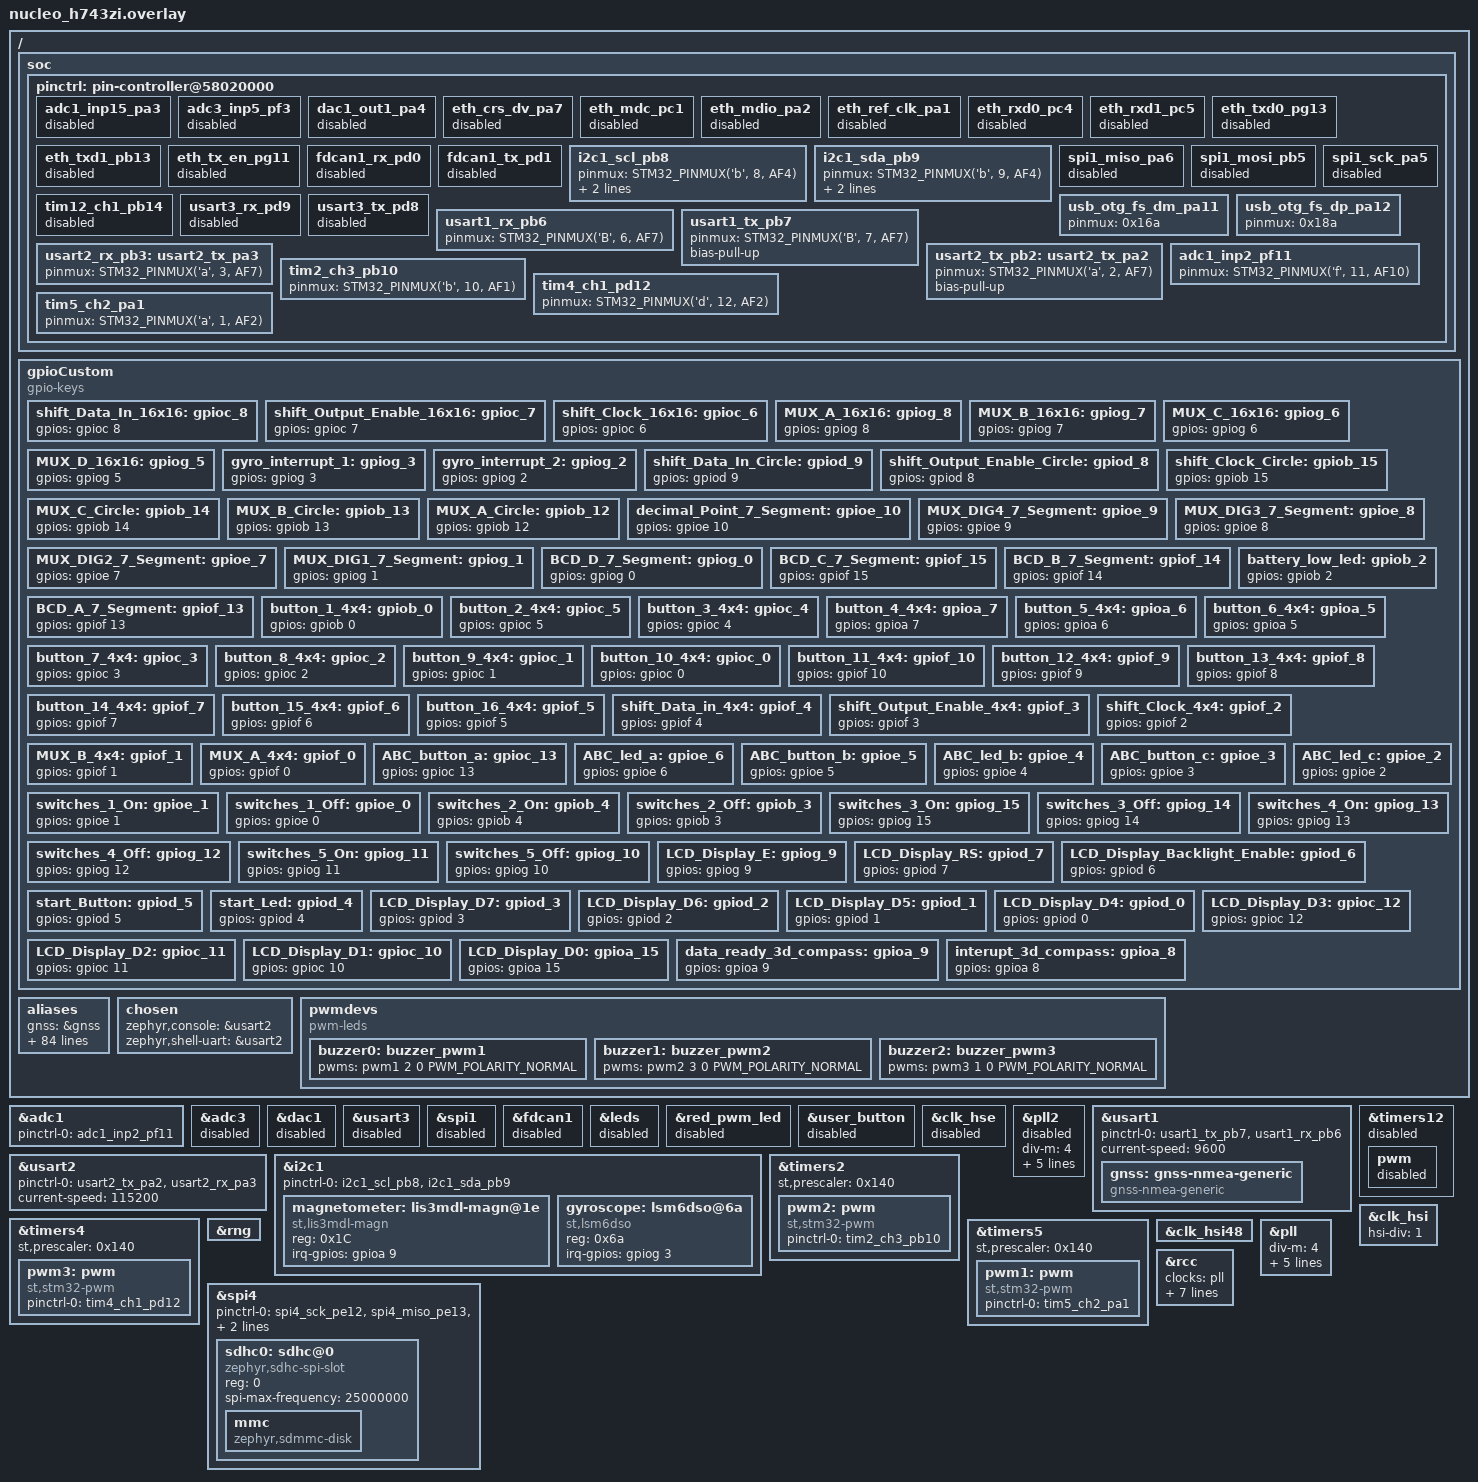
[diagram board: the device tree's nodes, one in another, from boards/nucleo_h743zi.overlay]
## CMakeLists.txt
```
# SPDX-License-Identifier: Apache-2.0

cmake_minimum_required(VERSION 3.20.0)
find_package(Zephyr REQUIRED HINTS $ENV{ZEPHYR_BASE})
project(startweek)

# Gather source files using wildcards for src directory
file(GLOB SRC_HARDWARE_SOURCES 			"../hardware/src/*.c")
file(GLOB SRC_HARDWARECONTROL_SOURCES 	"../hardwareControl/src/*.c")
file(GLOB SRC_MAIN_SOURCES 				"src/*.c")
file(GLOB SRC_STATES_SOURCES 			"../states/src/*.c")
file(GLOB SRC_STATEMACHINE 				"../main/src/statemachine.c")
file(GLOB SRC_THREADS 					"../main/src/threads.c")
file(GLOB SRC_HELPFUNC 					"../main/src/helperFunctions.c")

# Add your source files
target_sources(app PRIVATE 
    ${SRC_HARDWARE_SOURCES}
	${SRC_HARDWARECONTROL_SOURCES}
	${SRC_MAIN_SOURCES}
	${SRC_STATES_SOURCES}
	${SRC_STATEMACHINE}
	${SRC_THREADS}
	${SRC_HELPFUNC}
)

# Add include directories
target_include_directories(app PRIVATE
	${CMAKE_CURRENT_SOURCE_DIR}/../hardware/inc
	${CMAKE_CURRENT_SOURCE_DIR}/../hardwareControl/inc
	${CMAKE_CURRENT_SOURCE_DIR}/../main/inc
	${CMAKE_CURRENT_SOURCE_DIR}/../states/inc
	${CMAKE_CURRENT_SOURCE_DIR}/inc
)

set_property(TARGET app PROPERTY COMPILE_WARNING_AS_ERROR OFF)
```

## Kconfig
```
mainmenu "Startweek options"

menu ":D"

config TEST_RNG_INPUT
    bool "Use RNG input instead of human input"
    default y

config TEST_ACCELEROMETER
    bool "Test the accelerometer"
    default n

config TEST_BUTTONMATRIX
    bool "Test the buttonmatrix"
    default n

config TEST_CIRCLE_MATRIX
    bool "Test the circle matrix"
    default n

config TEST_GENERIC_GPIO
    bool "Test the generic GPIO"
    default n

config TEST_HELPER_FUNCTIONS
    bool "Test helper functions"
    default n

config TEST_INTEGRATION
    bool "Test integration"
    default n

config TEST_LCD
    bool "Test the LCD"
    default n

config TEST_LED_MATRIX
    bool "Test the LED matrix"
    default n

config TEST_SEVEN_SEGMENT
    bool "Test the seven-segment display"
    default n

config TEST_MINIGAME_FUNCTIONS
    bool "Test minigame functions"
    default n

endmenu

source "Kconfig.zephyr"
```

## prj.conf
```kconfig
CONFIG_COMPILER_WARNINGS_AS_ERRORS=y

CONFIG_TEST_RNG_INPUT=y
CONFIG_TEST_ACCELEROMETER=y
CONFIG_TEST_BUTTONMATRIX=y
CONFIG_TEST_CIRCLE_MATRIX=y
CONFIG_TEST_GENERIC_GPIO=y
CONFIG_TEST_HELPER_FUNCTIONS=y
CONFIG_TEST_INTEGRATION=n
CONFIG_TEST_LCD=y
CONFIG_TEST_LED_MATRIX=y
CONFIG_TEST_SEVEN_SEGMENT=y
CONFIG_TEST_MINIGAME_FUNCTIONS=y
```

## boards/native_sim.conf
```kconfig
CONFIG_LV_Z_MEM_POOL_SIZE=163840
CONFIG_LV_Z_SHELL=y
CONFIG_MAIN_STACK_SIZE=16384

CONFIG_GPIO=y
CONFIG_INPUT=y
CONFIG_LOG=y
CONFIG_SHELL=y

CONFIG_DISPLAY=y
CONFIG_EMUL=y
CONFIG_GPIO_EMUL=y
CONFIG_GPIO_EMUL_SDL=y
CONFIG_EMUL_LOG_LEVEL_DBG=y

# LVGL config
CONFIG_LVGL=y
CONFIG_LV_MEM_CUSTOM=y
CONFIG_LV_USE_LOG=y
CONFIG_LV_USE_LABEL=y
CONFIG_LV_USE_BTN=y
CONFIG_LV_USE_ARC=y
CONFIG_LV_USE_IMG=y

CONFIG_ENTROPY_GENERATOR=y

CONFIG_ZTEST=y
```

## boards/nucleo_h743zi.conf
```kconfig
CONFIG_GPIO=y
CONFIG_DEBUG_OPTIMIZATIONS=y
CONFIG_SIZE_OPTIMIZATIONS=n
CONFIG_SPEED_OPTIMIZATIONS=n
CONFIG_ENTROPY_GENERATOR=y

CONFIG_STDOUT_CONSOLE=y
CONFIG_CBPRINTF_FP_SUPPORT=y

CONFIG_I2C=y
CONFIG_SENSOR=y
CONFIG_LSM6DSO_TRIGGER_NONE=y
CONFIG_LIS3MDL_ODR="155"

CONFIG_LSM6DSO=y
CONFIG_LSM6DSO_TRIGGER_NONE=y
CONFIG_PWM=y

#CONFIG_GNSS=y
#CONFIG_GNSS_SATELLITES=y

#CONFIG_UART_INTERRUPT_DRIVEN=y
#CONFIG_MODEM_MODULES=y

#CONFIG_GNSS_SATELLITES=y
CONFIG_STM32_VREF=n
CONFIG_STM32_VBAT=n
CONFIG_STM32_TEMP=n

CONFIG_DISK_ACCESS=y
CONFIG_FILE_SYSTEM=y
#CONFIG_FILE_SYSTEM_SHELL=y
CONFIG_FAT_FILESYSTEM_ELM=y
CONFIG_MAIN_STACK_SIZE=2024
CONFIG_HEAP_MEM_POOL_SIZE=8192
CONFIG_ZTEST=y
```

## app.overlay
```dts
/ {
	soc {
		pinctrl: pin-controller@58020000 {
			//disable pins
			adc1_inp15_pa3: adc1_inp15_pa3 {
				status = "disabled";
			};
			adc3_inp5_pf3: adc3_inp5_pf3 {
				status = "disabled";
			};
			dac1_out1_pa4: dac1_out1_pa4 {
				status = "disabled";
			};
			eth_crs_dv_pa7: eth_crs_dv_pa7 {
				status = "disabled";
			};
			eth_mdc_pc1: eth_mdc_pc1 {
				status = "disabled";
			};
			eth_mdio_pa2: eth_mdio_pa2 {
				status = "disabled";
			};
			eth_ref_clk_pa1: eth_ref_clk_pa1 {
				status = "disabled";
			};
			eth_rxd0_pc4: eth_rxd0_pc4 {
				status = "disabled";
			};
			eth_rxd1_pc5: eth_rxd1_pc5 {
				status = "disabled";
			};
			eth_txd0_pg13: eth_txd0_pg13 {
				status = "disabled";
			};
			eth_txd1_pb13: eth_txd1_pb13 {
				status = "disabled";
			};
			eth_tx_en_pg11: eth_tx_en_pg11 {
				status = "disabled";
			};
			fdcan1_rx_pd0: fdcan1_rx_pd0 {
				status = "disabled";
			};
			fdcan1_tx_pd1: fdcan1_tx_pd1 {
				status = "disabled";
			};
			i2c1_scl_pb8: i2c1_scl_pb8 {
				status = "disabled";
			};
			i2c1_sda_pb9: i2c1_sda_pb9 {
				status = "disabled";
			};
			spi1_miso_pa6: spi1_miso_pa6 {
				status = "disabled";
			};
			spi1_mosi_pb5: spi1_mosi_pb5 {
				status = "disabled";
			};
			spi1_sck_pa5: spi1_sck_pa5 {
				status = "disabled";
			};
			tim12_ch1_pb14: tim12_ch1_pb14 {
				status = "okay";
			};
			usart3_rx_pd9: usart3_rx_pd9 {
				status = "disabled";
			};
			usart3_tx_pd8: usart3_tx_pd8 {
				status = "disabled";
			};

			//enable and configure pins
			usb_otg_fs_dm_pa11: usb_otg_fs_dm_pa11 {
				pinmux = < 0x16a >;
				phandle = < 0x22 >;
				status = "okay";
			};
			usb_otg_fs_dp_pa12: usb_otg_fs_dp_pa12 {
				pinmux = < 0x18a >;
				phandle = < 0x23 >;
				status = "okay";
			};
			usart1_rx_pb6: usart1_rx_pb6 {
				pinmux = <STM32_PINMUX('B', 6, AF7)>;
				status = "okay";
			};
			usart1_tx_pb7: usart1_tx_pb7 {
				pinmux = <STM32_PINMUX('B', 7, AF7)>;
				bias-pull-up;
				status = "okay";
			};
			usart2_rx_pb3: usart2_tx_pa3 {
				pinmux = <STM32_PINMUX('a', 3, AF7)>;
				status = "okay";
			};
			usart2_tx_pb2: usart2_tx_pa2 {
				pinmux = <STM32_PINMUX('a', 2, AF7)>;
				bias-pull-up;
				status = "okay";
			};
			i2c1_scl_pb8: i2c1_scl_pb8 {
				pinmux = < 0x304 >;
				bias-pull-up;
				drive-open-drain;
				status = "okay";
				phandle = < 0xb >;
			};
			i2c1_sda_pb9: i2c1_sda_pb9 {
				pinmux = < 0x324 >;
				bias-pull-up;
				drive-open-drain;
				status = "okay";
				phandle = < 0xc >;
			};
			adc1_inp2_pf11: adc1_inp2_pf11 {
				pinmux = <STM32_PINMUX('f', 11, AF10)>;
				status = "okay";
			};
		};
	};

	gpioCustom {
		compatible = "gpio-keys";

		shift_Data_In_16x16: gpioc_8 {
			gpios = <&gpioc 8 GPIO_ACTIVE_HIGH>;
		};
		shift_Output_Enable_16x16: gpioc_7 {
			gpios = <&gpioc 7 GPIO_ACTIVE_HIGH>;
		};
		shift_Clock_16x16: gpioc_6 {
			gpios = <&gpioc 6 GPIO_ACTIVE_HIGH>;
		};
		MUX_A_16x16: gpiog_8 {
			gpios = <&gpiog 8 GPIO_ACTIVE_HIGH>;
		};
		MUX_B_16x16: gpiog_7 {
			gpios = <&gpiog 7 GPIO_ACTIVE_HIGH>;
		};
		MUX_C_16x16: gpiog_6 {
			gpios = <&gpiog 6 GPIO_ACTIVE_HIGH>;
		};
		MUX_D_16x16: gpiog_5 {
			gpios = <&gpiog 5 GPIO_ACTIVE_HIGH>;
		};
		gyro_interrupt_1: gpiog_3 {
			gpios = <&gpiog 3 GPIO_ACTIVE_HIGH>;
		};
		gyro_interrupt_2: gpiog_2 {
			gpios = <&gpiog 2 GPIO_ACTIVE_HIGH>;
		};
		shift_Data_In_Circle: gpiod_9 {
			gpios = <&gpiod 9 GPIO_ACTIVE_HIGH>;
		};
		shift_Output_Enable_Circle: gpiod_8 {
			gpios = <&gpiod 8 GPIO_ACTIVE_HIGH>;
		};
		shift_Clock_Circle: gpiob_15 {
			gpios = <&gpiob 15 GPIO_ACTIVE_HIGH>;
		};
		MUX_C_Circle: gpiob_14 {
			gpios = <&gpiob 14 GPIO_ACTIVE_HIGH>;
		};
		MUX_B_Circle: gpiob_13 {
			gpios = <&gpiob 13 GPIO_ACTIVE_HIGH>;
		};
		MUX_A_Circle: gpiob_12 {
			gpios = <&gpiob 12 GPIO_ACTIVE_HIGH>;
		};
		buzzer3: gpioe_14 {
			gpios = <&gpioe 14 GPIO_ACTIVE_HIGH>;
		};
		buzzer2: gpioe_13 {
			gpios = <&gpioe 13 GPIO_ACTIVE_HIGH>;
		};
		buzzer1: gpioe_12 {
			gpios = <&gpioe 12 GPIO_ACTIVE_HIGH>;
		};
		decimal_Point_7_Segment: gpioe_10 {
			gpios = <&gpioe 10 GPIO_ACTIVE_HIGH>;
		};
		MUX_DIG4_7_Segment: gpioe_9 {
			gpios = <&gpioe 9 GPIO_ACTIVE_HIGH>;
		};
		MUX_DIG3_7_Segment: gpioe_8 {
			gpios = <&gpioe 8 GPIO_ACTIVE_HIGH>;
		};
		MUX_DIG2_7_Segment: gpioe_7 {
			gpios = <&gpioe 7 GPIO_ACTIVE_HIGH>;
		};
		MUX_DIG1_7_Segment: gpiog_1 {
			gpios = <&gpiog 1 GPIO_ACTIVE_HIGH>;
		};
		BCD_D_7_Segment: gpiog_0 {
			gpios = <&gpiog 0 GPIO_ACTIVE_HIGH>;
		};
		BCD_C_7_Segment: gpiof_15 {
			gpios = <&gpiof 15 GPIO_ACTIVE_HIGH>;
		};
		BCD_B_7_Segment: gpiof_14 {
			gpios = <&gpiof 14 GPIO_ACTIVE_HIGH>;
		};
		BCD_A_7_Segment: gpiof_13 {
			gpios = <&gpiof 13 GPIO_ACTIVE_HIGH>;
		};
		battery_low_led: gpiob_2 {
			gpios = <&gpiob 2 GPIO_ACTIVE_HIGH>;
		};
		button_1_4x4: gpiob_0 {
			gpios = <&gpiob 0 GPIO_PULL_UP>;
		};
		button_2_4x4: gpioc_5 {
			gpios = <&gpioc 5 GPIO_PULL_UP>;
		};
		button_3_4x4: gpioc_4 {
			gpios = <&gpioc 4 GPIO_PULL_UP>;
		};
		button_4_4x4: gpioa_7 {
			gpios = <&gpioa 7 GPIO_PULL_UP>;
		};
		button_5_4x4: gpioa_6 {
			gpios = <&gpioa 6 GPIO_PULL_UP>;
		};
		button_6_4x4: gpioa_5 {
			gpios = <&gpioa 5 GPIO_PULL_UP>;
		};
		button_7_4x4: gpioc_3 {
			gpios = <&gpioc 3 GPIO_PULL_UP>;
		};
		button_8_4x4: gpioc_2 {
			gpios = <&gpioc 2 GPIO_PULL_UP>;
		};
		button_9_4x4: gpioc_1 {
			gpios = <&gpioc 1 GPIO_PULL_UP>;
		};
		button_10_4x4: gpioc_0 {
			gpios = <&gpioc 0 GPIO_PULL_UP>;
		};
		button_11_4x4: gpiof_10 {
			gpios = <&gpiof 10 GPIO_PULL_UP>;
		};
		button_12_4x4: gpiof_9 {
			gpios = <&gpiof 9 GPIO_PULL_UP>;
		};
		button_13_4x4: gpiof_8 {
			gpios = <&gpiof 8 GPIO_PULL_UP>;
		};
		button_14_4x4: gpiof_7 {
			gpios = <&gpiof 7 GPIO_PULL_UP>;
		};
		button_15_4x4: gpiof_6 {
			gpios = <&gpiof 6 GPIO_PULL_UP>;
		};
		button_16_4x4: gpiof_5 {
			gpios = <&gpiof 5 GPIO_PULL_UP>;
		};
		shift_Data_in_4x4: gpiof_4 {
			gpios = <&gpiof 4 GPIO_ACTIVE_HIGH>;
		};
		shift_Output_Enable_4x4: gpiof_3 {
			gpios = <&gpiof 3 GPIO_ACTIVE_HIGH>;
		};
		shift_Clock_4x4: gpiof_2 {
			gpios = <&gpiof 2 GPIO_ACTIVE_HIGH>;
		};
		MUX_B_4x4: gpiof_1 {
			gpios = <&gpiof 1 GPIO_ACTIVE_HIGH>;
		};
		MUX_A_4x4: gpiof_0 {
			gpios = <&gpiof 0 GPIO_ACTIVE_HIGH>;
		};
		ABC_button_a: gpioc_13 {
			gpios = <&gpioc 13 GPIO_PULL_UP>;
		};
		ABC_led_a: gpioe_6 {
			gpios = <&gpioe 6 GPIO_ACTIVE_HIGH>;
		};
		ABC_button_b: gpioe_5 {
			gpios = <&gpioe 5 GPIO_PULL_UP>;
		};
		ABC_led_b: gpioe_4 {
			gpios = <&gpioe 4 GPIO_ACTIVE_HIGH>;
		};
		ABC_button_c: gpioe_3 {
			gpios = <&gpioe 3 GPIO_PULL_UP>;
		};
		ABC_led_c: gpioe_2 {
			gpios = <&gpioe 2 GPIO_ACTIVE_HIGH>;
		};
		switches_1_On: gpioe_1 {
			gpios = <&gpioe 1 GPIO_PULL_UP>;
		};
		switches_1_Off: gpioe_0 {
			gpios = <&gpioe 0 GPIO_PULL_UP>;
		};
		switches_2_On: gpiob_4 {
			gpios = <&gpiob 4 GPIO_PULL_UP>;
		};
		switches_2_Off: gpiob_3 {
			gpios = <&gpiob 3 GPIO_PULL_UP>;
		};
		switches_3_On: gpiog_15 {
			gpios = <&gpiog 15 GPIO_PULL_UP>;
		};
		switches_3_Off: gpiog_14 {
			gpios = <&gpiog 14 GPIO_PULL_UP>;
		};
		switches_4_On: gpiog_13 {
			gpios = <&gpiog 13 GPIO_PULL_UP>;
		};
		switches_4_Off: gpiog_12 {
			gpios = <&gpiog 12 GPIO_PULL_UP>;
		};
		switches_5_On: gpiog_11 {
			gpios = <&gpiog 11 GPIO_PULL_UP>;
		};
		switches_5_Off: gpiog_10 {
			gpios = <&gpiog 10 GPIO_PULL_UP>;
		};
		LCD_Display_E: gpiog_9 {
			gpios = <&gpiog 9 GPIO_ACTIVE_HIGH>;
		};
		LCD_Display_RS: gpiod_7 {
			gpios = <&gpiod 7 GPIO_ACTIVE_HIGH>;
		};
		LCD_Display_Backlight_Enable: gpiod_6 {
			gpios = <&gpiod 6 GPIO_ACTIVE_HIGH>;
		};
		start_Button: gpiod_5 {
			gpios = <&gpiod 5 GPIO_PULL_UP>;
		};
		start_Led: gpiod_4 {
			gpios = <&gpiod 4 GPIO_ACTIVE_HIGH>;
		};
		LCD_Display_D7: gpiod_3 {
			gpios = <&gpiod 3 GPIO_ACTIVE_HIGH>;
		};
		LCD_Display_D6: gpiod_2 {
			gpios = <&gpiod 2 GPIO_ACTIVE_HIGH>;
		};
		LCD_Display_D5: gpiod_1 {
			gpios = <&gpiod 1 GPIO_ACTIVE_HIGH>;
		};
		LCD_Display_D4: gpiod_0 {
			gpios = <&gpiod 0 GPIO_ACTIVE_HIGH>;
		};
		LCD_Display_D3: gpioc_12 {
			gpios = <&gpioc 12 GPIO_ACTIVE_HIGH>;
		};
		LCD_Display_D2: gpioc_11 {
			gpios = <&gpioc 11 GPIO_ACTIVE_HIGH>;
		};
		LCD_Display_D1: gpioc_10 {
			gpios = <&gpioc 10 GPIO_ACTIVE_HIGH>;
		};
		LCD_Display_D0: gpioa_15 {
			gpios = <&gpioa 15 GPIO_ACTIVE_HIGH>;
		};
		data_ready_3d_compass: gpioa_9 {
			gpios = <&gpioa 9 GPIO_PULL_UP>;
		};
		interupt_3d_compass: gpioa_8 {
			gpios = <&gpioa 8 GPIO_PULL_UP>;
		};

	};

	aliases {
		gnss = &gnss;
		shiftdatain16x16 = &shift_Data_In_16x16;
		shiftenable16x16 = &shift_Output_Enable_16x16;
		shiftclock16x16 = &shift_Clock_16x16;
		muxa16x16 = &MUX_A_16x16;
		muxb16x16 = &MUX_B_16x16;
		muxc16x16 = &MUX_C_16x16;
		muxd16x16 = &MUX_D_16x16;
		gyrointerrupt1 = &gyro_interrupt_1;
		gyrointerrupt2 = &gyro_interrupt_2;
		shiftdataincircle = &shift_Data_In_Circle;
		shiftoutputenablecircle = &shift_Output_Enable_Circle;
		shiftclockcircle = &shift_Clock_Circle;
		muxacircle = &MUX_A_Circle;
		muxbcircle = &MUX_B_Circle;
		muxccircle = &MUX_C_Circle;
		buzzer1 = &buzzer1;
		buzzer2 = &buzzer2;
		buzzer3 = &buzzer3;
		decimalpoint7segment = &decimal_Point_7_Segment;
		muxdig17segment = &MUX_DIG1_7_Segment;
		muxdig27segment = &MUX_DIG2_7_Segment;
		muxdig37segment = &MUX_DIG3_7_Segment;
		muxdig47segment = &MUX_DIG4_7_Segment;
		bcdd7segment = &BCD_D_7_Segment;
		bcdc7segment = &BCD_C_7_Segment;
		bcdb7segment = &BCD_B_7_Segment;
		bcda7segment = &BCD_A_7_Segment;
		batterylowled = &battery_low_led;		
		button14x4 = &button_1_4x4;
		button24x4 = &button_2_4x4;
		button34x4 = &button_3_4x4;
		button44x4 = &button_4_4x4;
		button54x4 = &button_5_4x4;
		button64x4 = &button_6_4x4;
		button74x4 = &button_7_4x4;
		button84x4 = &button_8_4x4;
		button94x4 = &button_9_4x4;
		button104x4 = &button_10_4x4;
		button114x4 = &button_11_4x4;
		button124x4 = &button_12_4x4;
		button134x4 = &button_13_4x4;
		button144x4 = &button_14_4x4;
		button154x4 = &button_15_4x4;
		button164x4 = &button_16_4x4;
		shiftdatain4x4 = &shift_Data_in_4x4;
		shiftoutputenable4x4 = &shift_Output_Enable_4x4;
		shiftclock4x4 = &shift_Clock_4x4;
		muxa4x4 = &MUX_A_4x4;
		muxb4x4 = &MUX_B_4x4;
		abcbuttona = &ABC_button_a;
		abcleda = &ABC_led_a;
		abcbuttonb = &ABC_button_b;
		abcledb = &ABC_led_b;
		abcbuttonc = &ABC_button_c;
		abcledc = &ABC_led_c;
		switches1on = &switches_1_On;
		switches1off = &switches_1_Off;
		switches2on = &switches_2_On;
		switches2off = &switches_2_Off;
		switches3on = &switches_3_On;
		switches3off = &switches_3_Off;
		switches4on = &switches_4_On;
		switches4off = &switches_4_Off;
		switches5on = &switches_5_On;
		switches5off = &switches_5_Off;
		lcddisplaye = &LCD_Display_E;
		lcddisplayrs = &LCD_Display_RS;
		lcddisplaybacklightenable = &LCD_Display_Backlight_Enable;
		startbutton = &start_Button;
		startled = &start_Led;
		lcddisplayd7 = &LCD_Display_D7;
		lcddisplayd6 = &LCD_Display_D6;
		lcddisplayd5 = &LCD_Display_D5;
		lcddisplayd4 = &LCD_Display_D4;
		lcddisplayd3 = &LCD_Display_D3;
		lcddisplayd2 = &LCD_Display_D2;
		lcddisplayd1 = &LCD_Display_D1;
		lcddisplayd0 = &LCD_Display_D0;
		3dcompassdataready = &data_ready_3d_compass;
		3dcompassintterupt = &interupt_3d_compass;
	};

	 chosen {
		zephyr,console = &usart2;
		zephyr,shell-uart = &usart2;
	};
};


//disable unused


&adc1{
		status = "okay";
		pinctrl-0 = < &adc1_inp2_pf11 >;
};

&adc3{
		status = "disabled";
};

&dac1{
		status = "disabled";
};

&usart3 {
		status = "disabled";
};

&spi1 {
		status = "disabled";
};

&fdcan1{
		status = "disabled";
};



&leds{
		status = "disabled";
};

&red_pwm_led {
		status = "disabled";
};

&user_button {
		status = "disabled";
};

&clk_hse {
		status = "disabled";
};

//enable used

&usart1 {
		pinctrl-0 = < &usart1_tx_pb7 &usart1_rx_pb6 >;
		pinctrl-names = "default";
        current-speed = <9600>;
        status = "okay";
        gnss: gnss-nmea-generic {
                compatible = "gnss-nmea-generic";
        };
};

&usart2 {
		pinctrl-0 = < &usart2_tx_pa2 &usart2_rx_pa3 >;
		pinctrl-names = "default";
        current-speed = <115200>;
        status = "okay";
};


&i2c1{
		status = "okay";
		pinctrl-0 = < &i2c1_scl_pb8 &i2c1_sda_pb9 >;
		gyro: lis3mdl-magn@1e {
			compatible = "st,lis3mdl-magn";
			reg = <0x1E>;
			irq-gpios = <&gpiob 8 GPIO_ACTIVE_HIGH>;
		};
};

&clk_hsi{
	status = "okay";
	hsi-div = <1>;
};

&clk_hsi48{
	status = "okay";
};

&rng{
	status = "okay";
};

&pll {
	div-m = <4>;
	mul-n = <40>;
	div-p = <2>;
	div-q = <3>;
	div-r = <2>;
	clocks = <&clk_hsi>;
	status = "okay";
};

&rcc {
	clocks = <&pll>;
	clock-frequency = <DT_FREQ_M(320)>;
	d1cpre = < 0x1 >;
	hpre = < 0x2 >;
	d1ppre = < 0x2 >;
	d2ppre1 = < 0x2 >;
	d2ppre2 = < 0x2 >;
	d3ppre = < 0x2 >;
};
```

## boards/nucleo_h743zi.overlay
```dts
/ {
	soc {
		pinctrl: pin-controller@58020000 {
			//disable pins
			adc1_inp15_pa3: adc1_inp15_pa3 {
				status = "disabled";
			};
			adc3_inp5_pf3: adc3_inp5_pf3 {
				status = "disabled";
			};
			dac1_out1_pa4: dac1_out1_pa4 {
				status = "disabled";
			};
			eth_crs_dv_pa7: eth_crs_dv_pa7 {
				status = "disabled";
			};
			eth_mdc_pc1: eth_mdc_pc1 {
				status = "disabled";
			};
			eth_mdio_pa2: eth_mdio_pa2 {
				status = "disabled";
			};
			eth_ref_clk_pa1: eth_ref_clk_pa1 {
				status = "disabled";
			};
			eth_rxd0_pc4: eth_rxd0_pc4 {
				status = "disabled";
			};
			eth_rxd1_pc5: eth_rxd1_pc5 {
				status = "disabled";
			};
			eth_txd0_pg13: eth_txd0_pg13 {
				status = "disabled";
			};
			eth_txd1_pb13: eth_txd1_pb13 {
				status = "disabled";
			};
			eth_tx_en_pg11: eth_tx_en_pg11 {
				status = "disabled";
			};
			fdcan1_rx_pd0: fdcan1_rx_pd0 {
				status = "disabled";
			};
			fdcan1_tx_pd1: fdcan1_tx_pd1 {
				status = "disabled";
			};
			i2c1_scl_pb8: i2c1_scl_pb8 {
				status = "okay";
			};
			i2c1_sda_pb9: i2c1_sda_pb9 {
				status = "okay";
			};
			spi1_miso_pa6: spi1_miso_pa6 {
				status = "disabled";
			};
			spi1_mosi_pb5: spi1_mosi_pb5 {
				status = "disabled";
			};
			spi1_sck_pa5: spi1_sck_pa5 {
				status = "disabled";
			};
			tim12_ch1_pb14: tim12_ch1_pb14 {
				status = "disabled";
			};
			usart3_rx_pd9: usart3_rx_pd9 {
				status = "disabled";
			};
			usart3_tx_pd8: usart3_tx_pd8 {
				status = "disabled";
			};

			//enable and configure pins
			usb_otg_fs_dm_pa11: usb_otg_fs_dm_pa11 {
				pinmux = < 0x16a >;
				phandle = < 0x22 >;
				status = "okay";
			};
			usb_otg_fs_dp_pa12: usb_otg_fs_dp_pa12 {
				pinmux = < 0x18a >;
				phandle = < 0x23 >;
				status = "okay";
			};
			usart1_rx_pb6: usart1_rx_pb6 {
				pinmux = <STM32_PINMUX('B', 6, AF7)>;
				status = "okay";
			};
			usart1_tx_pb7: usart1_tx_pb7 {
				pinmux = <STM32_PINMUX('B', 7, AF7)>;
				bias-pull-up;
				status = "okay";
			};
			usart2_rx_pb3: usart2_tx_pa3 {
				pinmux = <STM32_PINMUX('a', 3, AF7)>;
				status = "okay";
			};
			usart2_tx_pb2: usart2_tx_pa2 {
				pinmux = <STM32_PINMUX('a', 2, AF7)>;
				bias-pull-up;
				status = "okay";
			};
			i2c1_scl_pb8: i2c1_scl_pb8 {
				pinmux = <STM32_PINMUX('b', 8, AF4)>;
				bias-pull-up;
				drive-open-drain;
				status = "okay";
				phandle = < 0xb >;
			};
			i2c1_sda_pb9: i2c1_sda_pb9 {
				pinmux = <STM32_PINMUX('b', 9, AF4)>;
				bias-pull-up;
				drive-open-drain;
				status = "okay";
				phandle = < 0xc >;
			};
			adc1_inp2_pf11: adc1_inp2_pf11 {
				pinmux = <STM32_PINMUX('f', 11, AF10)>;
				status = "okay";
			};
			tim2_ch3_pb10: tim2_ch3_pb10{
				pinmux = <STM32_PINMUX('b', 10, AF1)>;
				status = "okay";
			};
			tim4_ch1_pd12: tim4_ch1_pd12{
				pinmux = <STM32_PINMUX('d', 12, AF2)>;
				status = "okay";
			};
			tim5_ch2_pa1: tim5_ch2_pa1{
				pinmux = <STM32_PINMUX('a', 1, AF2)>;
				status = "okay";
			};
		};
	};

	gpioCustom {
		compatible = "gpio-keys";

		shift_Data_In_16x16: gpioc_8 {
			gpios = <&gpioc 8 GPIO_ACTIVE_HIGH>;
		};
		shift_Output_Enable_16x16: gpioc_7 {
			gpios = <&gpioc 7 GPIO_ACTIVE_HIGH>;
		};
		shift_Clock_16x16: gpioc_6 {
			gpios = <&gpioc 6 GPIO_ACTIVE_HIGH>;
		};
		MUX_A_16x16: gpiog_8 {
			gpios = <&gpiog 8 GPIO_ACTIVE_HIGH>;
		};
		MUX_B_16x16: gpiog_7 {
			gpios = <&gpiog 7 GPIO_ACTIVE_HIGH>;
		};
		MUX_C_16x16: gpiog_6 {
			gpios = <&gpiog 6 GPIO_ACTIVE_HIGH>;
		};
		MUX_D_16x16: gpiog_5 {
			gpios = <&gpiog 5 GPIO_ACTIVE_HIGH>;
		};
		gyro_interrupt_1: gpiog_3 {
			gpios = <&gpiog 3 GPIO_ACTIVE_HIGH>;
		};
		gyro_interrupt_2: gpiog_2 {
			gpios = <&gpiog 2 GPIO_ACTIVE_HIGH>;
		};
		shift_Data_In_Circle: gpiod_9 {
			gpios = <&gpiod 9 GPIO_ACTIVE_HIGH>;
		};
		shift_Output_Enable_Circle: gpiod_8 {
			gpios = <&gpiod 8 GPIO_ACTIVE_HIGH>;
		};
		shift_Clock_Circle: gpiob_15 {
			gpios = <&gpiob 15 GPIO_ACTIVE_HIGH>;
		};
		MUX_C_Circle: gpiob_14 {
			gpios = <&gpiob 14 GPIO_ACTIVE_HIGH>;
		};
		MUX_B_Circle: gpiob_13 {
			gpios = <&gpiob 13 GPIO_ACTIVE_HIGH>;
		};
		MUX_A_Circle: gpiob_12 {
			gpios = <&gpiob 12 GPIO_ACTIVE_HIGH>;
		};
		decimal_Point_7_Segment: gpioe_10 {
			gpios = <&gpioe 10 GPIO_ACTIVE_HIGH>;
		};
		MUX_DIG4_7_Segment: gpioe_9 {
			gpios = <&gpioe 9 GPIO_ACTIVE_HIGH>;
		};
		MUX_DIG3_7_Segment: gpioe_8 {
			gpios = <&gpioe 8 GPIO_ACTIVE_HIGH>;
		};
		MUX_DIG2_7_Segment: gpioe_7 {
			gpios = <&gpioe 7 GPIO_ACTIVE_HIGH>;
		};
		MUX_DIG1_7_Segment: gpiog_1 {
			gpios = <&gpiog 1 GPIO_ACTIVE_HIGH>;
		};
		BCD_D_7_Segment: gpiog_0 {
			gpios = <&gpiog 0 GPIO_ACTIVE_HIGH>;
		};
		BCD_C_7_Segment: gpiof_15 {
			gpios = <&gpiof 15 GPIO_ACTIVE_HIGH>;
		};
		BCD_B_7_Segment: gpiof_14 {
			gpios = <&gpiof 14 GPIO_ACTIVE_HIGH>;
		};
		BCD_A_7_Segment: gpiof_13 {
			gpios = <&gpiof 13 GPIO_ACTIVE_HIGH>;
		};
		battery_low_led: gpiob_2 {
			gpios = <&gpiob 2 GPIO_ACTIVE_HIGH>;
		};
		button_1_4x4: gpiob_0 {
			gpios = <&gpiob 0 GPIO_PULL_UP>;
		};
		button_2_4x4: gpioc_5 {
			gpios = <&gpioc 5 GPIO_PULL_UP>;
		};
		button_3_4x4: gpioc_4 {
			gpios = <&gpioc 4 GPIO_PULL_UP>;
		};
		button_4_4x4: gpioa_7 {
			gpios = <&gpioa 7 GPIO_PULL_UP>;
		};
		button_5_4x4: gpioa_6 {
			gpios = <&gpioa 6 GPIO_PULL_UP>;
		};
		button_6_4x4: gpioa_5 {
			gpios = <&gpioa 5 GPIO_PULL_UP>;
		};
		button_7_4x4: gpioc_3 {
			gpios = <&gpioc 3 GPIO_PULL_UP>;
		};
		button_8_4x4: gpioc_2 {
			gpios = <&gpioc 2 GPIO_PULL_UP>;
		};
		button_9_4x4: gpioc_1 {
			gpios = <&gpioc 1 GPIO_PULL_UP>;
		};
		button_10_4x4: gpioc_0 {
			gpios = <&gpioc 0 GPIO_PULL_UP>;
		};
		button_11_4x4: gpiof_10 {
			gpios = <&gpiof 10 GPIO_PULL_UP>;
		};
		button_12_4x4: gpiof_9 {
			gpios = <&gpiof 9 GPIO_PULL_UP>;
		};
		button_13_4x4: gpiof_8 {
			gpios = <&gpiof 8 GPIO_PULL_UP>;
		};
		button_14_4x4: gpiof_7 {
			gpios = <&gpiof 7 GPIO_PULL_UP>;
		};
		button_15_4x4: gpiof_6 {
			gpios = <&gpiof 6 GPIO_PULL_UP>;
		};
		button_16_4x4: gpiof_5 {
			gpios = <&gpiof 5 GPIO_PULL_UP>;
		};
		shift_Data_in_4x4: gpiof_4 {
			gpios = <&gpiof 4 GPIO_ACTIVE_HIGH>;
		};
		shift_Output_Enable_4x4: gpiof_3 {
			gpios = <&gpiof 3 GPIO_ACTIVE_HIGH>;
		};
		shift_Clock_4x4: gpiof_2 {
			gpios = <&gpiof 2 GPIO_ACTIVE_HIGH>;
		};
		MUX_B_4x4: gpiof_1 {
			gpios = <&gpiof 1 GPIO_ACTIVE_HIGH>;
		};
		MUX_A_4x4: gpiof_0 {
			gpios = <&gpiof 0 GPIO_ACTIVE_HIGH>;
		};
		ABC_button_a: gpioc_13 {
			gpios = <&gpioc 13 GPIO_PULL_UP>;
		};
		ABC_led_a: gpioe_6 {
			gpios = <&gpioe 6 GPIO_ACTIVE_HIGH>;
		};
		ABC_button_b: gpioe_5 {
			gpios = <&gpioe 5 GPIO_PULL_UP>;
		};
		ABC_led_b: gpioe_4 {
			gpios = <&gpioe 4 GPIO_ACTIVE_HIGH>;
		};
		ABC_button_c: gpioe_3 {
			gpios = <&gpioe 3 GPIO_PULL_UP>;
		};
		ABC_led_c: gpioe_2 {
			gpios = <&gpioe 2 GPIO_ACTIVE_HIGH>;
		};
		switches_1_On: gpioe_1 {
			gpios = <&gpioe 1 GPIO_PULL_UP>;
		};
		switches_1_Off: gpioe_0 {
			gpios = <&gpioe 0 GPIO_PULL_UP>;
		};
		switches_2_On: gpiob_4 {
			gpios = <&gpiob 4 GPIO_PULL_UP>;
		};
		switches_2_Off: gpiob_3 {
			gpios = <&gpiob 3 GPIO_PULL_UP>;
		};
		switches_3_On: gpiog_15 {
			gpios = <&gpiog 15 GPIO_PULL_UP>;
		};
		switches_3_Off: gpiog_14 {
			gpios = <&gpiog 14 GPIO_PULL_UP>;
		};
		switches_4_On: gpiog_13 {
			gpios = <&gpiog 13 GPIO_PULL_UP>;
		};
		switches_4_Off: gpiog_12 {
			gpios = <&gpiog 12 GPIO_PULL_UP>;
		};
		switches_5_On: gpiog_11 {
			gpios = <&gpiog 11 GPIO_PULL_UP>;
		};
		switches_5_Off: gpiog_10 {
			gpios = <&gpiog 10 GPIO_PULL_UP>;
		};
		LCD_Display_E: gpiog_9 {
			gpios = <&gpiog 9 GPIO_ACTIVE_HIGH>;
		};
		LCD_Display_RS: gpiod_7 {
			gpios = <&gpiod 7 GPIO_ACTIVE_HIGH>;
		};
		LCD_Display_Backlight_Enable: gpiod_6 {
			gpios = <&gpiod 6 GPIO_ACTIVE_HIGH>;
		};
		start_Button: gpiod_5 {
			gpios = <&gpiod 5 GPIO_PULL_UP>;
		};
		start_Led: gpiod_4 {
			gpios = <&gpiod 4 GPIO_ACTIVE_HIGH>;
		};
		LCD_Display_D7: gpiod_3 {
			gpios = <&gpiod 3 GPIO_ACTIVE_HIGH>;
		};
		LCD_Display_D6: gpiod_2 {
			gpios = <&gpiod 2 GPIO_ACTIVE_HIGH>;
		};
		LCD_Display_D5: gpiod_1 {
			gpios = <&gpiod 1 GPIO_ACTIVE_HIGH>;
		};
		LCD_Display_D4: gpiod_0 {
			gpios = <&gpiod 0 GPIO_ACTIVE_HIGH>;
		};
		LCD_Display_D3: gpioc_12 {
			gpios = <&gpioc 12 GPIO_ACTIVE_HIGH>;
		};
		LCD_Display_D2: gpioc_11 {
			gpios = <&gpioc 11 GPIO_ACTIVE_HIGH>;
		};
		LCD_Display_D1: gpioc_10 {
			gpios = <&gpioc 10 GPIO_ACTIVE_HIGH>;
		};
		LCD_Display_D0: gpioa_15 {
			gpios = <&gpioa 15 GPIO_ACTIVE_HIGH>;
		};
		data_ready_3d_compass: gpioa_9 {
			gpios = <&gpioa 9 GPIO_PULL_UP>;
		};
		interupt_3d_compass: gpioa_8 {
			gpios = <&gpioa 8 GPIO_PULL_UP>;
		};

	};

	aliases {
		gnss = &gnss;
		shiftdatain16x16 = &shift_Data_In_16x16;
		shiftenable16x16 = &shift_Output_Enable_16x16;
		shiftclock16x16 = &shift_Clock_16x16;
		muxa16x16 = &MUX_A_16x16;
		muxb16x16 = &MUX_B_16x16;
		muxc16x16 = &MUX_C_16x16;
		muxd16x16 = &MUX_D_16x16;
		gyrointerrupt1 = &gyro_interrupt_1;
		gyrointerrupt2 = &gyro_interrupt_2;
		shiftdataincircle = &shift_Data_In_Circle;
		shiftoutputenablecircle = &shift_Output_Enable_Circle;
		shiftclockcircle = &shift_Clock_Circle;
		muxacircle = &MUX_A_Circle;
		muxbcircle = &MUX_B_Circle;
		muxccircle = &MUX_C_Circle;
		decimalpoint7segment = &decimal_Point_7_Segment;
		muxdig17segment = &MUX_DIG1_7_Segment;
		muxdig27segment = &MUX_DIG2_7_Segment;
		muxdig37segment = &MUX_DIG3_7_Segment;
		muxdig47segment = &MUX_DIG4_7_Segment;
		bcdd7segment = &BCD_D_7_Segment;
		bcdc7segment = &BCD_C_7_Segment;
		bcdb7segment = &BCD_B_7_Segment;
		bcda7segment = &BCD_A_7_Segment;
		batterylowled = &battery_low_led;		
		button14x4 = &button_1_4x4;
		button24x4 = &button_2_4x4;
		button34x4 = &button_3_4x4;
		button44x4 = &button_4_4x4;
		button54x4 = &button_5_4x4;
		button64x4 = &button_6_4x4;
		button74x4 = &button_7_4x4;
		button84x4 = &button_8_4x4;
		button94x4 = &button_9_4x4;
		button104x4 = &button_10_4x4;
		button114x4 = &button_11_4x4;
		button124x4 = &button_12_4x4;
		button134x4 = &button_13_4x4;
		button144x4 = &button_14_4x4;
		button154x4 = &button_15_4x4;
		button164x4 = &button_16_4x4;
		shiftdatain4x4 = &shift_Data_in_4x4;
		shiftoutputenable4x4 = &shift_Output_Enable_4x4;
		shiftclock4x4 = &shift_Clock_4x4;
		muxa4x4 = &MUX_A_4x4;
		muxb4x4 = &MUX_B_4x4;
		abcbuttona = &ABC_button_a;
		abcleda = &ABC_led_a;
		abcbuttonb = &ABC_button_b;
		abcledb = &ABC_led_b;
		abcbuttonc = &ABC_button_c;
		abcledc = &ABC_led_c;
		switches1on = &switches_1_On;
		switches1off = &switches_1_Off;
		switches2on = &switches_2_On;
		switches2off = &switches_2_Off;
		switches3on = &switches_3_On;
		switches3off = &switches_3_Off;
		switches4on = &switches_4_On;
		switches4off = &switches_4_Off;
		switches5on = &switches_5_On;
		switches5off = &switches_5_Off;
		lcddisplaye = &LCD_Display_E;
		lcddisplayrs = &LCD_Display_RS;
		lcddisplaybacklightenable = &LCD_Display_Backlight_Enable;
		startbutton = &start_Button;
		startled = &start_Led;
		lcddisplayd7 = &LCD_Display_D7;
		lcddisplayd6 = &LCD_Display_D6;
		lcddisplayd5 = &LCD_Display_D5;
		lcddisplayd4 = &LCD_Display_D4;
		lcddisplayd3 = &LCD_Display_D3;
		lcddisplayd2 = &LCD_Display_D2;
		lcddisplayd1 = &LCD_Display_D1;
		lcddisplayd0 = &LCD_Display_D0;
		buzzer0=&buzzer0;
		buzzer1=&buzzer1;
		buzzer2=&buzzer2;
		3dcompassdataready = &data_ready_3d_compass;
		3dcompassintterupt = &interupt_3d_compass;
		magnetometer=&magnetometer;
		gyroscope=&gyroscope;
	};

	 chosen {
		zephyr,console = &usart2;
		zephyr,shell-uart = &usart2;
	};

	pwmdevs {
		compatible = "pwm-leds";
		status = "okay";
		buzzer0: buzzer_pwm1 {
			pwms = 	<&pwm1 2 0 PWM_POLARITY_NORMAL>;
			status = "okay";
		};
		buzzer1: buzzer_pwm2 {
			pwms = 	<&pwm2 3 0 PWM_POLARITY_NORMAL>;
			status = "okay";
		};
		buzzer2: buzzer_pwm3 {
			pwms = 	<&pwm3 1 0 PWM_POLARITY_NORMAL>;
			status = "okay";
		};
	};
};


//disable unused


&adc1{
		status = "okay";
		pinctrl-0 = < &adc1_inp2_pf11 >;
};

&adc3{
		status = "disabled";
};

&dac1{
		status = "disabled";
};

&usart3 {
		status = "disabled";
};

&spi1 {
		status = "disabled";
};

&fdcan1{
		status = "disabled";
};

&leds{
		status = "disabled";
};

&red_pwm_led {
		status = "okay";
};

&user_button {
		status = "disabled";
};

&clk_hse {
		status = "disabled";
};

&pll2 {
	div-m = <4>;
	mul-n = <120>;
	div-p = <2>;
	div-q = <3>; /* gives 80MHz to the FDCAN */
	div-r = <2>;
	clocks = <&clk_hse>;
	status = "disabled";
};


//enable used

&usart1 {
		pinctrl-0 = < &usart1_tx_pb7 &usart1_rx_pb6 >;
		pinctrl-names = "default";
        current-speed = <9600>;
        status = "okay";
        gnss: gnss-nmea-generic {
                compatible = "gnss-nmea-generic";
        };
};

&usart2 {
		pinctrl-0 = < &usart2_tx_pa2 &usart2_rx_pa3 >;
		pinctrl-names = "default";
        current-speed = <115200>;
        status = "okay";
};


&i2c1{
		status = "okay";
		pinctrl-0 = < &i2c1_scl_pb8 &i2c1_sda_pb9 >;

		magnetometer: lis3mdl-magn@1e {
			compatible = "st,lis3mdl-magn";
			reg = <0x1C>;
			irq-gpios = <&gpioa 9 GPIO_ACTIVE_HIGH>;
		};

		gyroscope: lsm6dso@6a {
			compatible = "st,lsm6dso";
			reg = <0x6a>;
			irq-gpios = <&gpiog 3 GPIO_ACTIVE_HIGH>; //the selected pin is wrong. check schematic
		};
};

// &timers1{
// 	status = "okay";
// 	st,prescaler = < 0x140 >; 
// 	pwm1: pwm{
// 		compatible = "st,stm32-pwm";
// 		status = "okay";
// 		#pwm-cells = < 0x3 >;
// 		pinctrl-0 = < &tim1_ch1_pe9>;
// 		pinctrl-names = "default";
// 	};
// };

&timers2{
	status = "okay";
	st,prescaler = < 0x140 >; 
	pwm2: pwm{
		compatible = "st,stm32-pwm";
		status = "okay";
		#pwm-cells = < 0x3 >;
		pinctrl-0 = < &tim2_ch3_pb10>;
		pinctrl-names = "default";
	};
};

&timers4{
	status = "okay";
	st,prescaler = < 0x140 >; 
	pwm3: pwm{
		compatible = "st,stm32-pwm";
		status = "okay";
		#pwm-cells = < 0x3 >;
		pinctrl-0 = < &tim4_ch1_pd12>;
		pinctrl-names = "default";
	};
};

&timers5{
	status = "okay";
	st,prescaler = < 0x140 >; 
	pwm1: pwm{
		compatible = "st,stm32-pwm";
		status = "okay";
		#pwm-cells = < 0x3 >;
		pinctrl-0 = < &tim5_ch2_pa1>;
		pinctrl-names = "default";
	};
};

&timers12{
	status = "disabled";
	pwm{
		status = "disabled";
	};
};

&clk_hsi{
	status = "okay";
	hsi-div = <1>;
};

&clk_hsi48{
	status = "okay";
};

&rng{
	status = "okay";
};

&pll {
	div-m = <4>;
	mul-n = <40>;
	div-p = <2>;
	div-q = <3>;
	div-r = <2>;
	clocks = <&clk_hsi>;
	status = "okay";
};

&rcc {
	clocks = <&pll>;
	clock-frequency = <DT_FREQ_M(320)>;
	d1cpre = < 0x1 >;
	hpre = < 0x2 >;
	d1ppre = < 0x2 >;
	d2ppre1 = < 0x2 >;
	d2ppre2 = < 0x2 >;
	d3ppre = < 0x2 >;
};

&red_pwm_led{
	status = "disabled";
};

&spi4 {
		status = "okay";
		pinctrl-names = "default";
		pinctrl-0 = <&spi4_sck_pe12 &spi4_miso_pe13 &spi4_mosi_pe14>;
		cs-gpios = <&gpioe 11 GPIO_ACTIVE_LOW>;

        sdhc0: sdhc@0 {
                compatible = "zephyr,sdhc-spi-slot";
                reg = <0>;
                status = "okay";
                mmc {
                    compatible = "zephyr,sdmmc-disk";
                    status = "okay";
                };
                spi-max-frequency = <25000000>;
                //spi-clock-mode-cpol;
                //spi-clock-mode-cpha;
        };
};
```

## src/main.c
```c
/*
 * Copyright (c) 2016 Intel Corporation
 *
 * SPDX-License-Identifier: Apache-2.0
 */

#include <zephyr/ztest.h>
#include "threads.h"

ZTEST_SUITE(framework_tests, NULL, NULL, NULL, NULL, NULL);

/**
 * @brief Test Asserts
 *
 * This test verifies various assert macros provided by ztest.
 *
 */
ZTEST(framework_tests, test_assert)
{
	zassert_true(1, "1 was false");
	zassert_false(0, "0 was true");
	zassert_is_null(NULL, "NULL was not NULL");
	zassert_not_null("foo", "\"foo\" was NULL");
	zassert_equal(1, 1, "1 was not equal to 1");
	zassert_equal_ptr(NULL, NULL, "NULL was not equal to NULL");
}

#if defined(CONFIG_ARCH_POSIX)
#define STACKSIZE2 16000
#define TLVGL_PRIORITY 3

void lvgl_task_handler_loop() {
    while (1) {
		//k_cpu_idle();
        lv_task_handler();
		//for native_sim
        k_sleep(K_MSEC(1));
    }
}
#endif

void test_main(void)
{
#if defined(CONFIG_ARCH_POSIX)
	const struct device *display_dev;
	display_dev = DEVICE_DT_GET(DT_CHOSEN(zephyr_display));
	if (!device_is_ready(display_dev)) {
		printk("Device not ready, aborting test");
	}

	display_blanking_off(display_dev);

	setup_ui(lv_scr_act());
#endif
	disableAllThreads();

	ztest_run_all(NULL, false, 1, 1);

	ztest_verify_all_test_suites_ran();
}

#if defined(CONFIG_ARCH_POSIX)
K_THREAD_DEFINE(tlvgl_id, STACKSIZE2, lvgl_task_handler_loop, NULL, NULL, NULL, TLVGL_PRIORITY, 0, 0);
#endif
```

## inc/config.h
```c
// #define LED_MATRIX
// #define BUTTON_MATRIX
// #define CIRCLE_MATRIX
// #define GENERIC_GPIO
// #define LCD
// #define SEVEN_SEGMENT
#define INTEGRATION

#include "testIntegration.h"
// #include "testLedMatrix.h"
// #include "testButtonMatrix.h"
// #include "testCircleMatrix.h"
// #include "testGenericGpio.h"
// #include "testLcd.h"
// #include "testSevenSegment.h"
// #define LED_MATRIX
// #define BUTTON_MATRIX
// #define GYROCOMPASS

// #ifdef LED_MATRIX
// #include "testLedMatrix.h"
// #endif //LED_MATRIX

// #ifdef BUTTON_MATRIX
// #include "testButtonMatrix.h"
// #endif //BUTTON_MATRIX

// #ifdef GYROCOMPASS
// #include "testGyroCompass.h"
// #endif //GYROCOMPASS
```

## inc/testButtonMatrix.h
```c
// #include <zephyr/ztest.h>
#include "buttonMatrix.h"
```

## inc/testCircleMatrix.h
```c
// #include <zephyr/ztest.h>
#include "circleMatrix.h"
```

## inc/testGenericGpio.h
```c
// #include <zephyr/ztest.h>
#include "genericGpio.h"
```

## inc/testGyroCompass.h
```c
#include <zephyr/ztest.h>
#include "gyroCompass.h"
```

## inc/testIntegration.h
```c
// #include <zephyr/ztest.h>
#include "threads.h"
#include "lcd.h"
#include "genericGpio.h"
#include "initialize.h"
#include "configure.h"
```

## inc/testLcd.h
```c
// #include <zephyr/ztest.h>
#include "lcd.h"
```

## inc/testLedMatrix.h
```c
// #include <zephyr/ztest.h>
#include "ledMatrix.h"
```

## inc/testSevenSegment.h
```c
// #include <zephyr/ztest.h>
#include "sevenSegment.h"
```

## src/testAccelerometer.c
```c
#ifdef CONFIG_TEST_ACCELEROMETER

#include <zephyr/ztest.h>
#include "gyroCompass.h"


ZTEST_SUITE(testAccelerometer, NULL, NULL, NULL, NULL, NULL);
ZTEST_SUITE(testMagnetometer, NULL, NULL, NULL, NULL, NULL);
ZTEST_SUITE(testCompass, NULL, NULL, NULL, NULL, NULL);

ZTEST(testAccelerometer, test_accelerometer_init)
{
	bool a =  gyroscope_init();
	zassert_equal(a,0);
}

ZTEST(testAccelerometer, test_accelerometer_exit)
{
	bool a =  gyroscope_init();
	zassert_equal(a,0);
	a =  gyroscope_exit();
	zassert_equal(a,0);
}

ZTEST(testAccelerometer, test_accelerometer_get_acceleration)
{
	int16_t tempData[3];
	bool a =  gyroscope_init();
	zassert_equal(a,0);
	a = gyroscope_get_acceleration(tempData);
	zassert_equal(a,0);
}

ZTEST(testAccelerometer, test_magnetometer_get_gyro)
{
	float tempData[3] = {0};
	uint8_t b;
	bool a =  gyroscope_init();
	zassert_equal(a,0);
	b = gyroscope_get_gyro(tempData);
	zassert_equal(a,0);
}

ZTEST(testMagnetometer, test_magnetometer_init)
{
	bool a =  magnetometer_init();
	zassert_equal(a,0);
}

ZTEST(testMagnetometer, test_magnetometer_exit)
{
	bool a =  magnetometer_init();
	zassert_equal(a,0);
	a =  magnetometer_exit();
	zassert_equal(a,0);
}

ZTEST(testMagnetometer, test_magnetometer_get_magneto)
{
	int16_t tempData[3] = {0};
	bool a =  magnetometer_init();
	zassert_equal(a,0);
	a = magnetometer_get_magneto(tempData);
	zassert_equal(a,0);
}

ZTEST(testCompass, test_compass_get_heading)
{
	int tempData = 0;
	bool a =  magnetometer_init();
	zassert_equal(a,0);
	a = gyroscope_init();
	zassert_equal(a,0);
	a = gyroCompass_get_heading(&tempData);
	zassert_equal(a,0);
}
#endif
```

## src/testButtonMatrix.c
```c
#ifdef CONFIG_TEST_BUTTONMATRIX

#include <zephyr/ztest.h>
#include "buttonMatrix.h"

ZTEST_SUITE(testButtonMatrix, NULL, NULL, NULL, NULL, NULL);

ZTEST(testButtonMatrix, test_Matrix_Config_one)
{
	bool a =  buttonMatrixConfig();
	zassert_equal(a,0);
}

ZTEST(testButtonMatrix, test_Matrix_Init_one)
{	
	int8_t a = buttonMatrixInit();
	zassert_equal(a,0);
}

ZTEST(testButtonMatrix, test_Matrix_Set_one)
{
	int8_t data[4] = {0b11111111, 0b11111111, 0b11111111, 0b11111111};
	int8_t a = buttonMatrixSet(data);
	zassert_equal(a,0);
}

ZTEST(testButtonMatrix, test_Buttons_Config_one)
{
	bool a =  buttons4x4Config();
	zassert_equal(a,0);
}

ZTEST(testButtonMatrix, test_Buttons_Init_one)
{	
	int8_t a = buttons4x4Init();
	zassert_equal(a,0);
}

ZTEST(testButtonMatrix, test_Buttons_Get_one)
{
	for(uint8_t i = 0; i < 16; i++)
	{
		uint8_t a = buttons4x4Get(i);
		zassert_equal(a,1);
	}
}
#endif
```

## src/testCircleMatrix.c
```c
#ifdef CONFIG_TEST_CIRCLE_MATRIX

#include <zephyr/ztest.h>
#include "circleMatrix.h"

ZTEST_SUITE(testCircleMatrix, NULL, NULL, NULL, NULL, NULL);

ZTEST(testCircleMatrix, test_Config_one)
{
	bool a =  circleMatrixConfig();
	zassert_equal(a,0);
}

ZTEST(testCircleMatrix, test_Init_one)
{	
	int8_t a = circleMatrixInit();
	zassert_equal(a,0);
}

ZTEST(testCircleMatrix, test_Set_one)
{
	int8_t data[8] = 	{0b11111111, 0b11111111, 0b11111111, 0b11111111, 
						0b11111111, 0b11111111, 0b11111111, 0b11111111,
						};
	int8_t a = circleMatrixSet(data);
	zassert_equal(a,0);
}
#endif
```
